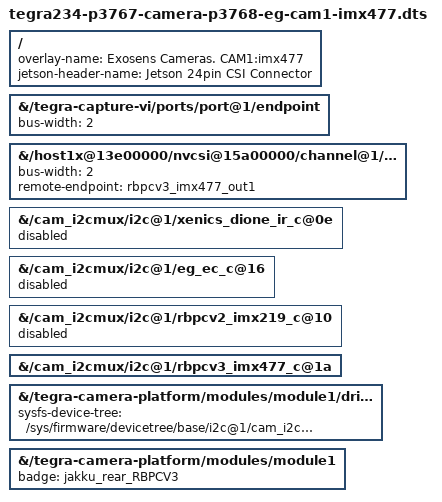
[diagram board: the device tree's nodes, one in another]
// SPDX-License-Identifier: GPL-2.0-only

/dts-v1/;
/plugin/;

#include <dt-common/jetson/tegra234-p3767-0000-common.h>

/ {
	overlay-name = "Exosens Cameras. CAM1:imx477";
	jetson-header-name = "Jetson 24pin CSI Connector";
	compatible = JETSON_COMPATIBLE_P3768;

	fragment@10 {
		target-path = "/tegra-capture-vi/ports/port@1/endpoint";
		__overlay__ {
			bus-width=<2>;
		};
	};

	fragment@11 {
		target-path = "/host1x@13e00000/nvcsi@15a00000/channel@1/ports/port@0/endpoint@2";
		__overlay__ {
			bus-width=<2>;
         remote-endpoint = <&rbpcv3_imx477_out1>;
		};
	};

   // Disable Dione cameras
	fragment@12 {
		target-path = "/cam_i2cmux/i2c@1/xenics_dione_ir_c@0e";
		__overlay__ {
         status = "disabled";
		};
	};

   // Disable EngineCore cameras
	fragment@13 {
		target-path = "/cam_i2cmux/i2c@1/eg_ec_c@16";
		__overlay__ {
         status = "disabled";
		};
	};

  // Disable other cameras 
	fragment@30 {
		target-path = "/cam_i2cmux/i2c@1/rbpcv2_imx219_c@10";
		__overlay__ {
         status = "disabled";
		};
	};

	// Enable imx477
	fragment@31 {
		target-path = "/cam_i2cmux/i2c@1/rbpcv3_imx477_c@1a";
		__overlay__ {
         status = "okay";
		};
	};

	fragment@32 {
		target-path = "/tegra-camera-platform/modules/module1/drivernode0";
		__overlay__ {
			sysfs-device-tree = "/sys/firmware/devicetree/base/i2c@1/cam_i2cmux/rbpcv3_imx477_c@1a";
		};
	};

	fragment@33 {
		target-path = "/tegra-camera-platform/modules/module1";
		__overlay__ {
			badge = "jakku_rear_RBPCV3";
		};
	};

};
